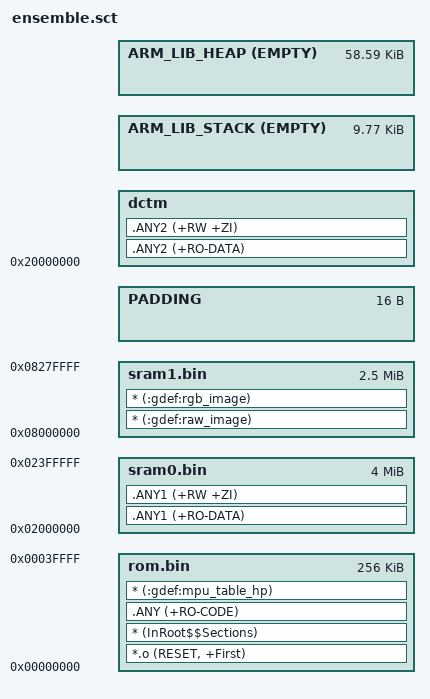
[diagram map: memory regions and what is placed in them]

; *************************************************************
; ***       Scatter-Loading Description File                ***
; *************************************************************

LOAD_REGION_MAIN       0x00000000 NOCOMPRESS
{
    ;-----------------------------------------------------
    ; Code region
    ;-----------------------------------------------------
    rom.bin         +0	0x00040000
    {
        *.o (RESET, +First)
        * (InRoot$$Sections)

        .ANY (+RO-CODE)
        * (:gdef:mpu_table_hp)
    }

    ; max ANY is what's left after stack and heap
    dctm          0x20000000 ANY_SIZE (0x100000-4000-30000) ALIGN 16
    {
        .ANY2 (+RO-DATA) ; ANY2 means map here first
        .ANY2 (+RW +ZI)
    }
    
    ; these have to come at the end b/c they don't take up load region space
    ARM_LIB_STACK +0 EMPTY ALIGN 8      10000
    {}

    ARM_LIB_HEAP  +0 EMPTY ALIGN 8      60000
    {}

    sram0.bin       0x02000000 ALIGN 16 0x00400000
    {
        ; Uncomment these to place model in SRAM, in case of a large model (image, etc)
        ; trained_model_compiled.o(*tensor_data*) ; use this for EON
        ; main.o(*trained_tflite) ; use this when not using EON Compiler
	    .ANY1 (+RO-DATA)
        .ANY1 (+RW +ZI)
    }
    sram1.bin		0x08000000 0x00280000
    {
    	* (:gdef:raw_image)
    	* (:gdef:rgb_image)
    }

    PADDING +0 ALIGN 16 FILL 0 16
    {
    }
}

; Remove the comments below if LOAD_REGION_MAIN is plced in NVM (after 0x80000000) - XIP mode

;LOAD_REGION_PARTITION 0x8057F000 0x1000
;{
;	RESERVED +0 FILL 0 (0x1000 - 16) {
;	}
;	ATOC (0x8057F000 + 0x1000 - 16) 16 {
;		*(:gdef:__mram_atoc)
;	}
;}
